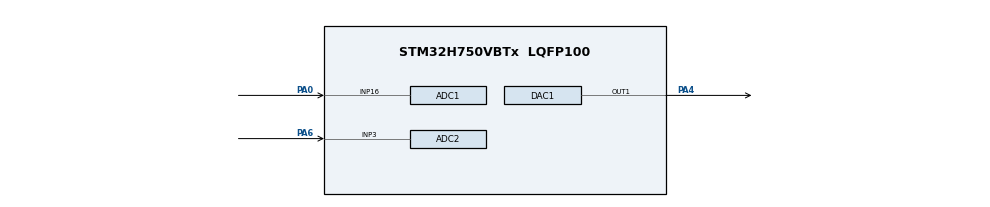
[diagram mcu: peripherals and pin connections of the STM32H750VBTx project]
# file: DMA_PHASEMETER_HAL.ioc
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ADC1.Channel-1\#ChannelRegularConversion=ADC_CHANNEL_16
ADC1.ClockPrescaler=ADC_CLOCK_SYNC_PCLK_DIV4
ADC1.ContinuousConvMode=ENABLE
ADC1.ConversionDataManagement=ADC_CONVERSIONDATA_DMA_CIRCULAR
ADC1.DMAAccessModeView=ENABLE
ADC1.EOCSelection=ADC_EOC_SINGLE_CONV
ADC1.Mode=ADC_DUALMODE_REGSIMULT
ADC1.NbrOfConversionFlag=1
ADC1.OffsetNumber-1\#ChannelRegularConversion=ADC_OFFSET_NONE
ADC1.OffsetSignedSaturation-1\#ChannelRegularConversion=DISABLE
ADC1.Overrun=ADC_OVR_DATA_OVERWRITTEN
ADC1.Rank-1\#ChannelRegularConversion=1
ADC1.Resolution=ADC_RESOLUTION_12B
ADC1.SamplingTime-1\#ChannelRegularConversion=ADC_SAMPLETIME_810CYCLES_5
ADC1.master=1
ADC2.Channel-0\#ChannelRegularConversion=ADC_CHANNEL_3
ADC2.ClockPrescaler=ADC_CLOCK_SYNC_PCLK_DIV4
ADC2.ContinuousConvMode=ENABLE
ADC2.DMAAccessModeView=ENABLE
ADC2.Mode=ADC_DUALMODE_REGSIMULT
ADC2.NbrOfConversionFlag=1
ADC2.OffsetNumber-0\#ChannelRegularConversion=ADC_OFFSET_NONE
ADC2.OffsetSignedSaturation-0\#ChannelRegularConversion=DISABLE
ADC2.Overrun=ADC_OVR_DATA_OVERWRITTEN
ADC2.Rank-0\#ChannelRegularConversion=1
ADC2.Resolution=ADC_RESOLUTION_12B
ADC2.SamplingTime-0\#ChannelRegularConversion=ADC_SAMPLETIME_810CYCLES_5
CORTEX_M7.CPU_DCache=Enabled
CORTEX_M7.CPU_ICache=Enabled
DAC1.DAC_Channel-DAC_OUT1=DAC_CHANNEL_1
Dma.ADC1.0.Direction=DMA_PERIPH_TO_MEMORY
Dma.ADC1.0.EventEnable=DISABLE
Dma.ADC1.0.FIFOMode=DMA_FIFOMODE_DISABLE
Dma.ADC1.0.Instance=DMA1_Stream0
Dma.ADC1.0.MemDataAlignment=DMA_MDATAALIGN_WORD
Dma.ADC1.0.MemInc=DMA_MINC_ENABLE
Dma.ADC1.0.Mode=DMA_CIRCULAR
Dma.ADC1.0.PeriphDataAlignment=DMA_PDATAALIGN_WORD
Dma.ADC1.0.PeriphInc=DMA_PINC_DISABLE
Dma.ADC1.0.Polarity=HAL_DMAMUX_REQ_GEN_RISING
Dma.ADC1.0.Priority=DMA_PRIORITY_LOW
Dma.ADC1.0.RequestNumber=1
Dma.ADC1.0.SignalID=NONE
Dma.ADC1.0.SyncEnable=DISABLE
Dma.ADC1.0.SyncPolarity=HAL_DMAMUX_SYNC_NO_EVENT
Dma.ADC1.0.SyncRequestNumber=1
Dma.ADC1.0.SyncSignalID=NONE
Dma.Request0=ADC1
Mcu.Family=STM32H7
Mcu.Name=STM32H750VBTx
Mcu.Package=LQFP100
NVIC.DMA1_Stream0_IRQn=true\:0\:0\:false\:false\:true\:false\:true
NVIC.PriorityGroup=NVIC_PRIORITYGROUP_4
PA0.Mode=IN16-Single-Ended
PA0.Signal=ADC1_INP16
PA13\ (JTMS/SWDIO).Mode=Serial_Wire
PA13\ (JTMS/SWDIO).Signal=DEBUG_JTMS-SWDIO
PA14\ (JTCK/SWCLK).Mode=Serial_Wire
PA14\ (JTCK/SWCLK).Signal=DEBUG_JTCK-SWCLK
PA4.Signal=COMP_DAC11_group
PA6.Signal=ADCx_INP3
PH0-OSC_IN\ (PH0).Mode=HSE-External-Oscillator
PH0-OSC_IN\ (PH0).Signal=RCC_OSC_IN
PH1-OSC_OUT\ (PH1).Mode=HSE-External-Oscillator
PH1-OSC_OUT\ (PH1).Signal=RCC_OSC_OUT
ProjectManager.HeapSize=0x200
ProjectManager.StackSize=0x400
ProjectManager.TargetToolchain=STM32CubeIDE
RCC.ADCFreq_Value=75000000
RCC.APB1Freq_Value=118750000
RCC.APB2Freq_Value=118750000
RCC.APB3Freq_Value=118750000
RCC.APB4Freq_Value=118750000
RCC.CortexFreq_Value=475000000
RCC.D1PPRE=RCC_APB3_DIV2
RCC.D2PPRE1=RCC_APB1_DIV2
RCC.D2PPRE2=RCC_APB2_DIV2
RCC.D3PPRE=RCC_APB4_DIV2
RCC.DIVM1=2
RCC.DIVM2=2
RCC.DIVN1=76
RCC.DIVN2=12
RCC.HCLKFreq_Value=237500000
RCC.HPRE=RCC_HCLK_DIV2
RCC.PLL2FRACN=0
RCC.PLLFRACN=0
RCC.PLLSourceVirtual=RCC_PLLSOURCE_HSE
RCC.PWR_Regulator_Voltage_Scale=PWR_REGULATOR_VOLTAGE_SCALE0
RCC.ProductRev=revV
RCC.SYSCLKFreq_VALUE=475000000
RCC.SYSCLKSource=RCC_SYSCLKSOURCE_PLLCLK
RCC.USBFreq_Value=475000000
SH.ADCx_INP3.0=ADC2_INP3,IN3-Single-Ended
SH.COMP_DAC11_group.0=DAC1_OUT1,DAC_OUT1
board=custom

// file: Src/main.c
/* USER CODE BEGIN Header */
/**
  ******************************************************************************
  * @file           : main.c
  * @brief          : Main program body
  ******************************************************************************
  * @attention
  *
  * <h2><center>&copy; Copyright (c) 2021 STMicroelectronics.
  * All rights reserved.</center></h2>
  *
  * This software component is licensed by ST under BSD 3-Clause license,
  * the "License"; You may not use this file except in compliance with the
  * License. You may obtain a copy of the License at:
  *                        opensource.org/licenses/BSD-3-Clause
  *
  ******************************************************************************
  */
/* USER CODE END Header */
#include "main.h"

#define ADC_CONVERTED_DATA_BUFFER_SIZE   ((uint32_t)  2)

ADC_HandleTypeDef hadc1;
ADC_HandleTypeDef hadc2;
DMA_HandleTypeDef hdma_adc1;

DAC_HandleTypeDef hdac1;

ALIGN_32BYTES (static uint16_t   ADC_Data[ADC_CONVERTED_DATA_BUFFER_SIZE]);
static uint32_t Uout = 1000; // Initial value of the phase shift can be shifted from zero to ensure that it will not drop below zero

void SystemClock_Config(void);
static void MX_GPIO_Init(void);
static void MX_DMA_Init(void);
static void MX_ADC1_Init(void);
static void MX_ADC2_Init(void);
static void MX_DAC1_Init(void);
volatile uint8_t DMA_flag = 0;

int main(void)
{
  /* USER CODE BEGIN 1 */
	const uint16_t Multiplier[6][4] = {{16384, 4096, 67, 20}, {8192, 2048, 67, 40}, {4096, 1024, 67, 80}, {2048, 512, 67, 160}, {1024, 256, 67, 320}, {512, 128, 67, 640}};

	const uint16_t upV = 2000;
	const uint16_t dwV = 550;

	int8_t zone;

	int16_t fi_ref, fi_curr;
	int8_t n;
	uint8_t channel;
	uint8_t Scale = 3;

  /* USER CODE END 1 */

  /* Enable I-Cache---------------------------------------------------------*/
  SCB_EnableICache();

  /* Enable D-Cache---------------------------------------------------------*/
  SCB_EnableDCache();

  /* MCU Configuration--------------------------------------------------------*/

  /* Reset of all peripherals, Initializes the Flash interface and the Systick. */
  HAL_Init();

  /* Configure the system clock */
  SystemClock_Config();

  /* Initialize all configured peripherals */
  MX_GPIO_Init();
  MX_DMA_Init();
  MX_ADC1_Init();
  MX_ADC2_Init();
  MX_DAC1_Init();
  /* USER CODE BEGIN 2 */
  HAL_DAC_Start(&hdac1, DAC_CHANNEL_1); // Enable and start DAC

  HAL_ADC_Start(&hadc2); // Enabling the second ADC
  HAL_ADCEx_MultiModeStart_DMA(&hadc1, (uint32_t *)ADC_Data, 1); // Enabling the main ADC and start conversion
  /* USER CODE END 2 */
	/* Determination the initial working zone */
	if (ADC_Data[0] > ADC_Data[1])
	{
	  if (ADC_Data[1] < dwV)
		  zone = 0;
	  else
		  zone = 1;
	}
	else
	{
	  if (ADC_Data[1] > upV)
		  zone = 2;
	  else
		  zone = 3;
	}
	/* Determination the initial working zone */

	/* Sign determination of the slope angle of the characteristic   */
	if ((zone / 2) == 0)
	  n = 1;
	else
	  n = -1;
	/* Sign determination of the slope angle of the characteristic   */

	channel = (zone % 2); // Determination of an AD8302 detector which is in the linear region

	fi_ref = (zone * Multiplier[Scale][1]) + n * (ADC_Data[channel] - 1229) * Multiplier[Scale][2] / Multiplier[Scale][3]; // Initial phase shift

	while (1) // Unconditional loop
	{
	  if (DMA_flag) // Wait for the conversion flag
	  {
		  /* Check for the working zone */
		  if (ADC_Data[channel] > upV)
		  {
			  zone = zone + n;
			  if (zone == 4)
			  {
				  zone = 0;
				  fi_ref = fi_ref - Multiplier[Scale][0];
			  }
			  else if (zone == -1)
			  {
				  zone = 3;
				  fi_ref = fi_ref + Multiplier[Scale][0];
			  }
			  if ((zone / 2) == 0)
				  n = 1;
			  else
				  n = -1;
			  channel = (zone % 2);
		  }
		  else if (ADC_Data[channel] < dwV)
		  {
			  zone = zone - n;
			  if (zone == 4)
			  {
				  zone = 0;
				  fi_ref = fi_ref - Multiplier[Scale][0];
			  }
			  else if (zone == -1)
			  {
				  zone = 3;
				  fi_ref = fi_ref + Multiplier[Scale][0];
			  }
			  if ((zone / 2) == 0)
				  n = 1;
			  else
				  n = -1;
			  channel = (zone % 2);
		  }
		  /* Check for the working zone */

		  fi_curr = (zone * Multiplier[Scale][1]) + n * (ADC_Data[channel] - 1229) * Multiplier[Scale][2] / Multiplier[Scale][3]; // Define the current phase shift compared to the initial time

		  //if (Uout + (fi_curr - fi_ref) > 0) // Prevent overflow due to phase noise at the initial time (if needed)
			  //Uout = Uout + (fi_curr - fi_ref);

		  fi_ref = fi_curr; // Saving the current value

		  DMA_flag = 0; // Clear the flag

		  HAL_DAC_SetValue(&hdac1, DAC_CHANNEL_1, DAC_ALIGN_12B_R, (uint16_t)(Uout/16)); // Transfer the calculated value to the DAC output
	  }
	}
}

void HAL_ADC_ConvCpltCallback(ADC_HandleTypeDef* hadc)  //
{
  SCB_InvalidateDCache_by_Addr((uint32_t *) &ADC_Data[1], 1); // DMA complete transition callback
  DMA_flag = 1;
}

void HAL_ADC_ConvHalfCpltCallback(ADC_HandleTypeDef* hadc) // DMA half transition callback
{
  SCB_InvalidateDCache_by_Addr((uint32_t *) &ADC_Data[0], 1); // Read data from the first AD8302
}

void HAL_ADC_ErrorCallback (ADC_HandleTypeDef * hadc)
{
	__NOP();
}

void SystemClock_Config(void)
{
  RCC_OscInitTypeDef RCC_OscInitStruct = {0};
  RCC_ClkInitTypeDef RCC_ClkInitStruct = {0};

  /** Supply configuration update enable
  */
  HAL_PWREx_ConfigSupply(PWR_LDO_SUPPLY);
  /** Configure the main internal regulator output voltage
  */
  __HAL_PWR_VOLTAGESCALING_CONFIG(PWR_REGULATOR_VOLTAGE_SCALE0);

  while(!__HAL_PWR_GET_FLAG(PWR_FLAG_VOSRDY)) {}
  /** Initializes the RCC Oscillators according to the specified parameters
  * in the RCC_OscInitTypeDef structure.
  */
  RCC_OscInitStruct.OscillatorType = RCC_OSCILLATORTYPE_HSE;
  RCC_OscInitStruct.HSEState = RCC_HSE_ON;
  RCC_OscInitStruct.PLL.PLLState = RCC_PLL_ON;
  RCC_OscInitStruct.PLL.PLLSource = RCC_PLLSOURCE_HSE;
  RCC_OscInitStruct.PLL.PLLM = 2;
  RCC_OscInitStruct.PLL.PLLN = 76;
  RCC_OscInitStruct.PLL.PLLP = 2;
  RCC_OscInitStruct.PLL.PLLQ = 2;
  RCC_OscInitStruct.PLL.PLLR = 2;
  RCC_OscInitStruct.PLL.PLLRGE = RCC_PLL1VCIRANGE_3;
  RCC_OscInitStruct.PLL.PLLVCOSEL = RCC_PLL1VCOWIDE;
  RCC_OscInitStruct.PLL.PLLFRACN = 0;
  if (HAL_RCC_OscConfig(&RCC_OscInitStruct) != HAL_OK)
  {
    Error_Handler();
  }
  /** Initializes the CPU, AHB and APB buses clocks
  */
  RCC_ClkInitStruct.ClockType = RCC_CLOCKTYPE_HCLK|RCC_CLOCKTYPE_SYSCLK
                              |RCC_CLOCKTYPE_PCLK1|RCC_CLOCKTYPE_PCLK2
                              |RCC_CLOCKTYPE_D3PCLK1|RCC_CLOCKTYPE_D1PCLK1;
  RCC_ClkInitStruct.SYSCLKSource = RCC_SYSCLKSOURCE_PLLCLK;
  RCC_ClkInitStruct.SYSCLKDivider = RCC_SYSCLK_DIV1;
  RCC_ClkInitStruct.AHBCLKDivider = RCC_HCLK_DIV2;
  RCC_ClkInitStruct.APB3CLKDivider = RCC_APB3_DIV2;
  RCC_ClkInitStruct.APB1CLKDivider = RCC_APB1_DIV2;
  RCC_ClkInitStruct.APB2CLKDivider = RCC_APB2_DIV2;
  RCC_ClkInitStruct.APB4CLKDivider = RCC_APB4_DIV2;

  if (HAL_RCC_ClockConfig(&RCC_ClkInitStruct, FLASH_LATENCY_4) != HAL_OK)
  {
    Error_Handler();
  }
}

static void MX_ADC1_Init(void)
{

  ADC_MultiModeTypeDef multimode = {0};
  ADC_ChannelConfTypeDef sConfig = {0};

  /** Common config
  */
  hadc1.Instance = ADC1;
  hadc1.Init.ClockPrescaler = ADC_CLOCK_SYNC_PCLK_DIV4;
  hadc1.Init.Resolution = ADC_RESOLUTION_12B;
  hadc1.Init.ScanConvMode = ADC_SCAN_DISABLE;
  hadc1.Init.EOCSelection = ADC_EOC_SINGLE_CONV;
  hadc1.Init.LowPowerAutoWait = DISABLE;
  hadc1.Init.ContinuousConvMode = ENABLE;
  hadc1.Init.NbrOfConversion = 1;
  hadc1.Init.DiscontinuousConvMode = DISABLE;
  hadc1.Init.ExternalTrigConv = ADC_SOFTWARE_START;
  hadc1.Init.ExternalTrigConvEdge = ADC_EXTERNALTRIGCONVEDGE_NONE;
  hadc1.Init.ConversionDataManagement = ADC_CONVERSIONDATA_DMA_CIRCULAR;
  hadc1.Init.Overrun = ADC_OVR_DATA_OVERWRITTEN;
  hadc1.Init.LeftBitShift = ADC_LEFTBITSHIFT_NONE;
  hadc1.Init.OversamplingMode = DISABLE;
  if (HAL_ADC_Init(&hadc1) != HAL_OK)
  {
    Error_Handler();
  }
  /** Configure the ADC multi-mode
  */
  multimode.Mode = ADC_DUALMODE_REGSIMULT;
  multimode.DualModeData = ADC_DUALMODEDATAFORMAT_32_10_BITS;
  multimode.TwoSamplingDelay = ADC_TWOSAMPLINGDELAY_1CYCLE;
  if (HAL_ADCEx_MultiModeConfigChannel(&hadc1, &multimode) != HAL_OK)
  {
    Error_Handler();
  }
  /** Configure Regular Channel
  */
  sConfig.Channel = ADC_CHANNEL_16;
  sConfig.Rank = ADC_REGULAR_RANK_1;
  sConfig.SamplingTime = ADC_SAMPLETIME_810CYCLES_5;
  sConfig.SingleDiff = ADC_SINGLE_ENDED;
  sConfig.OffsetNumber = ADC_OFFSET_NONE;
  sConfig.Offset = 0;
  sConfig.OffsetSignedSaturation = DISABLE;
  if (HAL_ADC_ConfigChannel(&hadc1, &sConfig) != HAL_OK)
  {
    Error_Handler();
  }

}

static void MX_ADC2_Init(void)
{

  ADC_ChannelConfTypeDef sConfig = {0};

  /** Common config
  */
  hadc2.Instance = ADC2;
  hadc2.Init.ClockPrescaler = ADC_CLOCK_SYNC_PCLK_DIV4;
  hadc2.Init.Resolution = ADC_RESOLUTION_12B;
  hadc2.Init.ScanConvMode = ADC_SCAN_DISABLE;
  hadc2.Init.EOCSelection = ADC_EOC_SINGLE_CONV;
  hadc2.Init.LowPowerAutoWait = DISABLE;
  hadc2.Init.ContinuousConvMode = ENABLE;
  hadc2.Init.NbrOfConversion = 1;
  hadc2.Init.DiscontinuousConvMode = DISABLE;
  hadc2.Init.ConversionDataManagement = ADC_CONVERSIONDATA_DR;
  hadc2.Init.Overrun = ADC_OVR_DATA_OVERWRITTEN;
  hadc2.Init.LeftBitShift = ADC_LEFTBITSHIFT_NONE;
  hadc2.Init.OversamplingMode = DISABLE;
  if (HAL_ADC_Init(&hadc2) != HAL_OK)
  {
    Error_Handler();
  }
  /** Configure Regular Channel
  */
  sConfig.Channel = ADC_CHANNEL_3;
  sConfig.Rank = ADC_REGULAR_RANK_1;
  sConfig.SamplingTime = ADC_SAMPLETIME_810CYCLES_5;
  sConfig.SingleDiff = ADC_SINGLE_ENDED;
  sConfig.OffsetNumber = ADC_OFFSET_NONE;
  sConfig.Offset = 0;
  sConfig.OffsetSignedSaturation = DISABLE;
  if (HAL_ADC_ConfigChannel(&hadc2, &sConfig) != HAL_OK)
  {
    Error_Handler();
  }

}

static void MX_DAC1_Init(void)
{

  DAC_ChannelConfTypeDef sConfig = {0};

  /** DAC Initialization
  */
  hdac1.Instance = DAC1;
  if (HAL_DAC_Init(&hdac1) != HAL_OK)
  {
    Error_Handler();
  }
  /** DAC channel OUT1 config
  */
  sConfig.DAC_SampleAndHold = DAC_SAMPLEANDHOLD_DISABLE;
  sConfig.DAC_Trigger = DAC_TRIGGER_NONE;
  sConfig.DAC_OutputBuffer = DAC_OUTPUTBUFFER_ENABLE;
  sConfig.DAC_ConnectOnChipPeripheral = DAC_CHIPCONNECT_DISABLE;
  sConfig.DAC_UserTrimming = DAC_TRIMMING_FACTORY;
  if (HAL_DAC_ConfigChannel(&hdac1, &sConfig, DAC_CHANNEL_1) != HAL_OK)
  {
    Error_Handler();
  }

}

static void MX_DMA_Init(void)
{

  /* DMA controller clock enable */
  __HAL_RCC_DMA1_CLK_ENABLE();

  /* DMA interrupt init */
  /* DMA1_Stream0_IRQn interrupt configuration */
  HAL_NVIC_SetPriority(DMA1_Stream0_IRQn, 0, 0);
  HAL_NVIC_EnableIRQ(DMA1_Stream0_IRQn);

}

static void MX_GPIO_Init(void)
{

  /* GPIO Ports Clock Enable */
  __HAL_RCC_GPIOH_CLK_ENABLE();
  __HAL_RCC_GPIOA_CLK_ENABLE();

}

void Error_Handler(void)
{
  __disable_irq();
  while (1)
  {
  }
}

/************************ (C) COPYRIGHT STMicroelectronics *****END OF FILE****/
